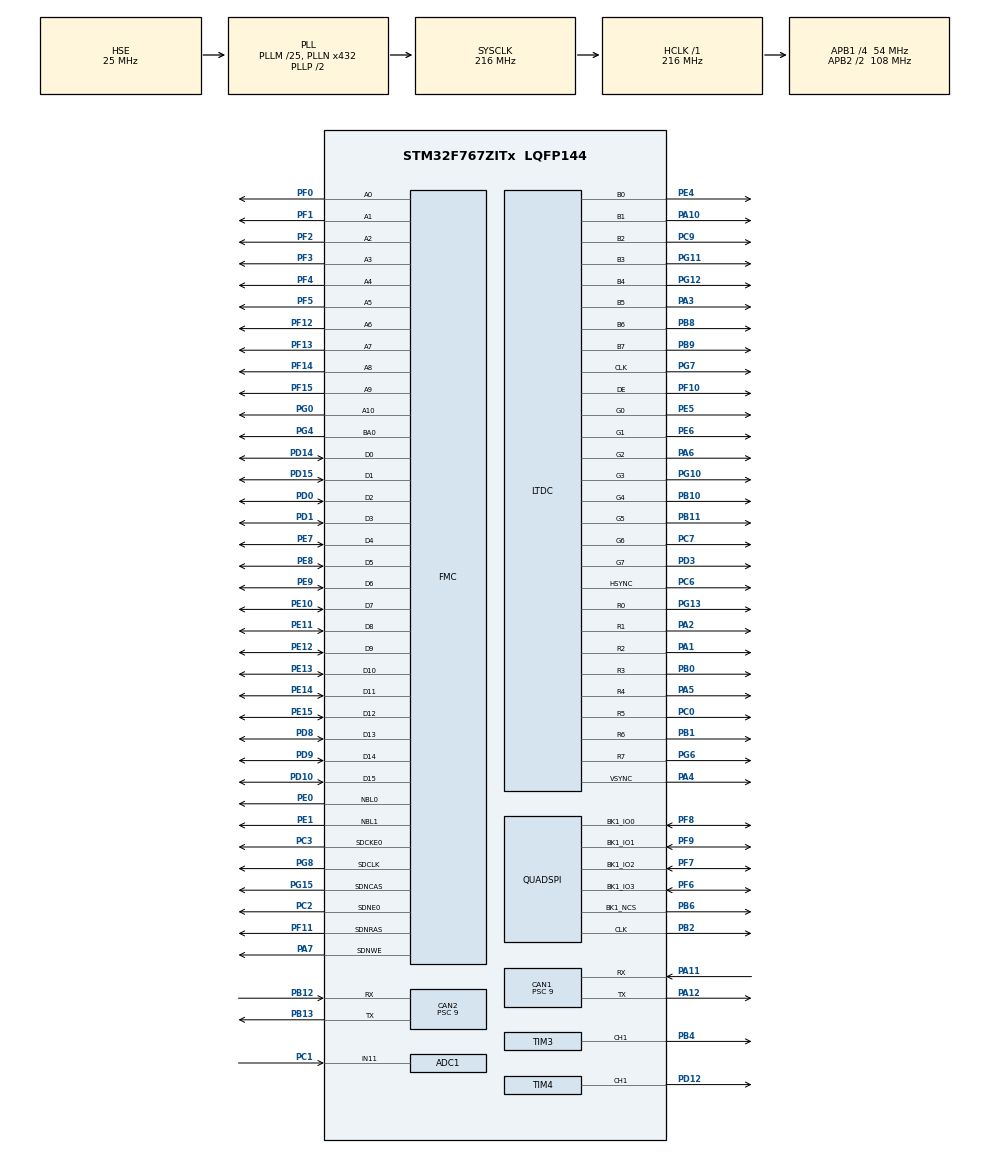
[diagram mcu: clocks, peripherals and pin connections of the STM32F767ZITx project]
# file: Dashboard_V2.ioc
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ADC1.Channel-0\#ChannelRegularConversion=ADC_CHANNEL_11
ADC1.Channel-1\#ChannelRegularConversion=ADC_CHANNEL_TEMPSENSOR
ADC1.ExternalTrigConv=ADC_EXTERNALTRIGCONV_T8_TRGO
ADC1.NbrOfConversion=2
ADC1.NbrOfConversionFlag=1
ADC1.Rank-0\#ChannelRegularConversion=1
ADC1.Rank-1\#ChannelRegularConversion=2
ADC1.SamplingTime-0\#ChannelRegularConversion=ADC_SAMPLETIME_480CYCLES
ADC1.SamplingTime-1\#ChannelRegularConversion=ADC_SAMPLETIME_480CYCLES
ADC1.ScanConvMode=ADC_SCAN_ENABLE
ADC1.master=1
CAN1.BS1=CAN_BS1_2TQ
CAN1.BS2=CAN_BS2_3TQ
CAN1.CalculateBaudRate=999999
CAN1.CalculateTimeBit=1000
CAN1.CalculateTimeQuantum=166.66666666666669
CAN1.NART=ENABLE
CAN1.Prescaler=9
CAN1.SJW=CAN_SJW_2TQ
CAN2.BS1=CAN_BS1_2TQ
CAN2.BS2=CAN_BS2_3TQ
CAN2.CalculateBaudRate=999999
CAN2.CalculateTimeBit=1000
CAN2.CalculateTimeQuantum=166.66666666666669
CAN2.NART=ENABLE
CAN2.Prescaler=9
CAN2.SJW=CAN_SJW_2TQ
DMA2D.ColorMode=DMA2D_OUTPUT_RGB888
Dma.Request0=TIM3_CH1/TRIG
Dma.Request1=TIM4_CH1
Dma.TIM3_CH1/TRIG.0.Direction=DMA_PERIPH_TO_MEMORY
Dma.TIM3_CH1/TRIG.0.FIFOMode=DMA_FIFOMODE_DISABLE
Dma.TIM3_CH1/TRIG.0.Instance=DMA1_Stream4
Dma.TIM3_CH1/TRIG.0.MemDataAlignment=DMA_MDATAALIGN_HALFWORD
Dma.TIM3_CH1/TRIG.0.MemInc=DMA_MINC_ENABLE
Dma.TIM3_CH1/TRIG.0.Mode=DMA_NORMAL
Dma.TIM3_CH1/TRIG.0.PeriphDataAlignment=DMA_PDATAALIGN_HALFWORD
Dma.TIM3_CH1/TRIG.0.PeriphInc=DMA_PINC_DISABLE
Dma.TIM3_CH1/TRIG.0.Priority=DMA_PRIORITY_LOW
Dma.TIM4_CH1.1.Direction=DMA_PERIPH_TO_MEMORY
Dma.TIM4_CH1.1.FIFOMode=DMA_FIFOMODE_DISABLE
Dma.TIM4_CH1.1.Instance=DMA1_Stream0
Dma.TIM4_CH1.1.MemDataAlignment=DMA_MDATAALIGN_HALFWORD
Dma.TIM4_CH1.1.MemInc=DMA_MINC_ENABLE
Dma.TIM4_CH1.1.Mode=DMA_NORMAL
Dma.TIM4_CH1.1.PeriphDataAlignment=DMA_PDATAALIGN_HALFWORD
Dma.TIM4_CH1.1.PeriphInc=DMA_PINC_DISABLE
Dma.TIM4_CH1.1.Priority=DMA_PRIORITY_LOW
FMC.CASLatency1=FMC_SDRAM_CAS_LATENCY_2
FMC.ExitSelfRefreshDelay1=7
FMC.LoadToActiveDelay1=2
FMC.RCDDelay1=2
FMC.RPDelay1=2
FMC.RPDelay2=2
FMC.ReadBurst1=FMC_SDRAM_RBURST_ENABLE
FMC.ReadBurst2=FMC_SDRAM_RBURST_ENABLE
FMC.RowCycleDelay1=6
FMC.RowCycleDelay2=6
FMC.SDClockPeriod1=FMC_SDRAM_CLOCK_PERIOD_2
FMC.SDClockPeriod2=FMC_SDRAM_CLOCK_PERIOD_2
FMC.SelfRefreshTime1=4
FMC.WriteRecoveryTime1=3
FREERTOS.Tasks01=hardwareTask,24,128,StartHardwareTask,Default,NULL,Dynamic,NULL,NULL;RPMLed,8,128,startRPMLed,Default,NULL,Dynamic,NULL,NULL;touchGFXTask,40,32768,startTouchGFXTask,Default,NULL,Dynamic,NULL,NULL;statusLedTask,8,128,startStatusLedTask,Default,NULL,Dynamic,NULL,NULL;DisplayDashboar,8,128,StartDisplayDashoard,Default,NULL,Dynamic,NULL,NULL
FREERTOS.configTOTAL_HEAP_SIZE=204800
JPEG.USE_JPEG_ENCODER=1
LTDC.ActiveW=800
LTDC.Alpha_L0=255
LTDC.FBStartAdress_L0=0xC0000000
LTDC.HBP=8
LTDC.HFP=8
LTDC.HSync=4
LTDC.ImageHeight_L0=480
LTDC.ImageWidth_L0=800
LTDC.Layers=0
LTDC.VBP=8
LTDC.VFP=8
LTDC.VSync=40
LTDC.WindowX1_L0=800
LTDC.WindowY1_L0=480
Mcu.Family=STM32F7
Mcu.Name=STM32F767ZITx
Mcu.Package=LQFP144
NVIC.ADC_IRQn=true\:5\:0\:false\:false\:true\:true\:true\:true\:true
NVIC.DMA1_Stream0_IRQn=true\:5\:0\:false\:false\:true\:true\:false\:true\:true
NVIC.DMA1_Stream4_IRQn=true\:5\:0\:false\:false\:true\:true\:false\:true\:true
NVIC.LTDC_IRQn=true\:5\:0\:false\:false\:true\:true\:true\:true\:true
NVIC.PriorityGroup=NVIC_PRIORITYGROUP_4
NVIC.TIM6_DAC_IRQn=true\:15\:0\:false\:false\:true\:false\:false\:true\:true
NVIC.TimeBase=TIM6_DAC_IRQn
NVIC.TimeBaseIP=TIM6
PA1.Mode=RGB888
PA1.Signal=LTDC_R2
PA10.Mode=RGB888
PA10.Signal=LTDC_B1
PA11.Mode=CAN_Activate
PA11.Signal=CAN1_RX
PA12.Mode=CAN_Activate
PA12.Signal=CAN1_TX
PA13.Mode=Trace_Asynchronous_SW
PA13.Signal=SYS_JTMS-SWDIO
PA14.Mode=Trace_Asynchronous_SW
PA14.Signal=SYS_JTCK-SWCLK
PA2.Mode=RGB888
PA2.Signal=LTDC_R1
PA3.Mode=RGB888
PA3.Signal=LTDC_B5
PA4.Mode=RGB888
PA4.Signal=LTDC_VSYNC
PA5.Mode=RGB888
PA5.Signal=LTDC_R4
PA6.Mode=RGB888
PA6.Signal=LTDC_G2
PA7.Signal=FMC_SDNWE
PB0.Mode=RGB888
PB0.Signal=LTDC_R3
PB1.Mode=RGB888
PB1.Signal=LTDC_R6
PB10.Mode=RGB888
PB10.Signal=LTDC_G4
PB11.Mode=RGB888
PB11.Signal=LTDC_G5
PB12.Mode=CAN_Activate
PB12.Signal=CAN2_RX
PB13.Mode=CAN_Activate
PB13.Signal=CAN2_TX
PB2.Mode=Single Bank 1
PB2.Signal=QUADSPI_CLK
PB3.Mode=Trace_Asynchronous_SW
PB3.Signal=SYS_JTDO-SWO
PB4.Signal=S_TIM3_CH1
PB6.Mode=Single Bank 1
PB6.Signal=QUADSPI_BK1_NCS
PB8.Mode=RGB888
PB8.Signal=LTDC_B6
PB9.Mode=RGB888
PB9.Signal=LTDC_B7
PC0.Mode=RGB888
PC0.Signal=LTDC_R5
PC1.Signal=ADCx_IN11
PC2.Mode=SdramChipSelect1_1
PC2.Signal=FMC_SDNE0
PC3.Mode=SdramChipSelect1_1
PC3.Signal=FMC_SDCKE0
PC6.Mode=RGB888
PC6.Signal=LTDC_HSYNC
PC7.Mode=RGB888
PC7.Signal=LTDC_G6
PC9.Mode=RGB888
PC9.Signal=LTDC_B2
PD0.Signal=FMC_D2_DA2
PD1.Signal=FMC_D3_DA3
PD10.Signal=FMC_D15_DA15
PD12.Signal=S_TIM4_CH1
PD14.Signal=FMC_D0_DA0
PD15.Signal=FMC_D1_DA1
PD3.Mode=RGB888
PD3.Signal=LTDC_G7
PD8.Signal=FMC_D13_DA13
PD9.Signal=FMC_D14_DA14
PE0.Signal=FMC_NBL0
PE1.Signal=FMC_NBL1
PE10.Signal=FMC_D7_DA7
PE11.Signal=FMC_D8_DA8
PE12.Signal=FMC_D9_DA9
PE13.Signal=FMC_D10_DA10
PE14.Signal=FMC_D11_DA11
PE15.Signal=FMC_D12_DA12
PE4.Mode=RGB888
PE4.Signal=LTDC_B0
PE5.Mode=RGB888
PE5.Signal=LTDC_G0
PE6.Mode=RGB888
PE6.Signal=LTDC_G1
PE7.Signal=FMC_D4_DA4
PE8.Signal=FMC_D5_DA5
PE9.Signal=FMC_D6_DA6
PF0.Signal=FMC_A0
PF1.Signal=FMC_A1
PF10.Mode=RGB888
PF10.Signal=LTDC_DE
PF11.Signal=FMC_SDNRAS
PF12.Signal=FMC_A6
PF13.Signal=FMC_A7
PF14.Signal=FMC_A8
PF15.Signal=FMC_A9
PF2.Signal=FMC_A2
PF3.Signal=FMC_A3
PF4.Signal=FMC_A4
PF5.Signal=FMC_A5
PF6.Mode=Single Bank 1
PF6.Signal=QUADSPI_BK1_IO3
PF7.Mode=Single Bank 1
PF7.Signal=QUADSPI_BK1_IO2
PF8.Mode=Single Bank 1
PF8.Signal=QUADSPI_BK1_IO0
PF9.Mode=Single Bank 1
PF9.Signal=QUADSPI_BK1_IO1
PG0.Signal=FMC_A10
PG10.Mode=RGB888
PG10.Signal=LTDC_G3
PG11.Mode=RGB888
PG11.Signal=LTDC_B3
PG12.Mode=RGB888
PG12.Signal=LTDC_B4
PG13.Mode=RGB888
PG13.Signal=LTDC_R0
PG15.Signal=FMC_SDNCAS
PG4.Signal=FMC_A14_BA0
PG6.Mode=RGB888
PG6.Signal=LTDC_R7
PG7.Mode=RGB888
PG7.Signal=LTDC_CLK
PG8.Signal=FMC_SDCLK
PH0/OSC_IN.Mode=HSE-External-Oscillator
PH0/OSC_IN.Signal=RCC_OSC_IN
PH1/OSC_OUT.Mode=HSE-External-Oscillator
PH1/OSC_OUT.Signal=RCC_OSC_OUT
ProjectManager.HeapSize=0x200
ProjectManager.StackSize=0x400
ProjectManager.TargetToolchain=STM32CubeIDE
QUADSPI.ChipSelectHighTime=QSPI_CS_HIGH_TIME_6_CYCLE
QUADSPI.ClockPrescaler=3
QUADSPI.FlashSize=23
QUADSPI.SampleShifting=QSPI_SAMPLE_SHIFTING_HALFCYCLE
RCC.AHBFreq_Value=216000000
RCC.APB1CLKDivider=RCC_HCLK_DIV4
RCC.APB1Freq_Value=54000000
RCC.APB1TimFreq_Value=108000000
RCC.APB2CLKDivider=RCC_HCLK_DIV2
RCC.APB2Freq_Value=108000000
RCC.APB2TimFreq_Value=216000000
RCC.CortexFreq_Value=216000000
RCC.HCLKFreq_Value=216000000
RCC.HSE_VALUE=25000000
RCC.HSI_VALUE=16000000
RCC.LSE_VALUE=32768
RCC.PLLM=25
RCC.PLLN=432
RCC.PLLSAIN=279
RCC.PLLSAIR=3
RCC.PLLSAIRDiv=RCC_PLLSAIDIVR_4
RCC.PLLSourceVirtual=RCC_PLLSOURCE_HSE
RCC.SYSCLKFreq_VALUE=216000000
RCC.SYSCLKSource=RCC_SYSCLKSOURCE_PLLCLK
RCC.USBFreq_Value=216000000
RCC.VCOOutputFreq_Value=432000000
SH.ADCx_IN11.0=ADC1_IN11,IN11
SH.FMC_A0.0=FMC_A0,11b-sda1
SH.FMC_A1.0=FMC_A1,11b-sda1
SH.FMC_A10.0=FMC_A10,11b-sda1
SH.FMC_A14_BA0.0=FMC_BA0,TwoSdramBanks1
SH.FMC_A2.0=FMC_A2,11b-sda1
SH.FMC_A3.0=FMC_A3,11b-sda1
SH.FMC_A4.0=FMC_A4,11b-sda1
SH.FMC_A5.0=FMC_A5,11b-sda1
SH.FMC_A6.0=FMC_A6,11b-sda1
SH.FMC_A7.0=FMC_A7,11b-sda1
SH.FMC_A8.0=FMC_A8,11b-sda1
SH.FMC_A9.0=FMC_A9,11b-sda1
SH.FMC_D0_DA0.0=FMC_D0,sd-16b-d1
SH.FMC_D10_DA10.0=FMC_D10,sd-16b-d1
SH.FMC_D11_DA11.0=FMC_D11,sd-16b-d1
SH.FMC_D12_DA12.0=FMC_D12,sd-16b-d1
SH.FMC_D13_DA13.0=FMC_D13,sd-16b-d1
SH.FMC_D14_DA14.0=FMC_D14,sd-16b-d1
SH.FMC_D15_DA15.0=FMC_D15,sd-16b-d1
SH.FMC_D1_DA1.0=FMC_D1,sd-16b-d1
SH.FMC_D2_DA2.0=FMC_D2,sd-16b-d1
SH.FMC_D3_DA3.0=FMC_D3,sd-16b-d1
SH.FMC_D4_DA4.0=FMC_D4,sd-16b-d1
SH.FMC_D5_DA5.0=FMC_D5,sd-16b-d1
SH.FMC_D6_DA6.0=FMC_D6,sd-16b-d1
SH.FMC_D7_DA7.0=FMC_D7,sd-16b-d1
SH.FMC_D8_DA8.0=FMC_D8,sd-16b-d1
SH.FMC_D9_DA9.0=FMC_D9,sd-16b-d1
SH.FMC_NBL0.0=FMC_NBL0,Sd2ByteEnable1
SH.FMC_NBL1.0=FMC_NBL1,Sd2ByteEnable1
SH.FMC_SDCLK.0=FMC_SDCLK,11b-sda1
SH.FMC_SDNCAS.0=FMC_SDNCAS,11b-sda1
SH.FMC_SDNRAS.0=FMC_SDNRAS,11b-sda1
SH.FMC_SDNWE.0=FMC_SDNWE,11b-sda1
SH.S_TIM3_CH1.0=TIM3_CH1,PWM Generation1 CH1
SH.S_TIM4_CH1.0=TIM4_CH1,PWM Generation1 CH1
STMicroelectronics.X-CUBE-TOUCHGFX.4.20.0.ApplicationCcGraphicsJjApplication=TouchGFXOoGenerator
STMicroelectronics.X-CUBE-TOUCHGFX.4.20.0.tgfx_address1=0xC0000000
STMicroelectronics.X-CUBE-TOUCHGFX.4.20.0.tgfx_display_interface=disp_ltdc
STMicroelectronics.X-CUBE-TOUCHGFX.4.20.0.tgfx_hardware_accelerator=dma_2d
STMicroelectronics.X-CUBE-TOUCHGFX.4.20.0.tgfx_location=By Address
STMicroelectronics.X-CUBE-TOUCHGFX.4.20.0.tgfx_video=Hardware
STMicroelectronics.X-CUBE-TOUCHGFX.4.20.0.tgfx_vsync=vsync_ltdc
STMicroelectronics.X-CUBE-TOUCHGFX.4.20.0_IsPackSelfContextualization=true
TIM3.Channel-PWM\ Generation1\ CH1=TIM_CHANNEL_1
TIM3.Period=134
TIM4.Channel-PWM\ Generation1\ CH1=TIM_CHANNEL_1
TIM4.Period=215
TIM8.Channel-PWM\ Generation1\ No\ Output=TIM_CHANNEL_1
TIM8.Period=5000-1
TIM8.Prescaler=216-1
VP_ADC1_TempSens_Input.Mode=IN-TempSens
VP_CRC_VS_CRC.Mode=CRC_Activate
VP_DMA2D_VS_DMA2D.Mode=DMA2D_Activate
VP_FREERTOS_VS_CMSIS_V2.Mode=CMSIS_V2
VP_JPEG_VS_JPEG.Mode=JPEG_Activate
VP_STMicroelectronics.X-CUBE-TOUCHGFX_VS_GraphicsJjApplication_4.20.0.Mode=GraphicsJjApplication
VP_SYS_VS_tim6.Mode=TIM6
VP_TIM3_VS_ClockSourceINT.Mode=Internal
VP_TIM4_VS_ClockSourceINT.Mode=Internal
VP_TIM8_VS_ClockSourceINT.Mode=Internal
VP_TIM8_VS_no_output1.Mode=PWM Generation1 No Output
board=custom

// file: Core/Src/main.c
/* USER CODE BEGIN Header */
/**
  ******************************************************************************
  * @file           : main.c
  * @brief          : Main program body
  ******************************************************************************
  * @attention
  *
  * <h2><center>&copy; Copyright (c) 2021 STMicroelectronics.
  * All rights reserved.</center></h2>
  *
  * This software component is licensed by ST under Ultimate Liberty license
  * SLA0044, the "License"; You may not use this file except in compliance with
  * the License. You may obtain a copy of the License at:
  *                             www.st.com/SLA0044
  *
  ******************************************************************************
  */
/* USER CODE END Header */
#include "main.h"
#include "cmsis_os.h"
#include "adc.h"
#include "can.h"
#include "crc.h"
#include "dma.h"
#include "dma2d.h"
#include "jpeg.h"
#include "ltdc.h"
#include "quadspi.h"
#include "tim.h"
#include "gpio.h"
#include "fmc.h"
#include "app_touchgfx.h"

/* USER CODE BEGIN Includes */
#include "at25sf128a.h"
#include "structs/ecumaster.h"

/* USER CODE END Includes */

void SystemClock_Config(void);
void MX_FREERTOS_Init(void);

int main(void)
{

  /* MCU Configuration--------------------------------------------------------*/

  /* Reset of all peripherals, Initializes the Flash interface and the Systick. */
  HAL_Init();

  /* Configure the system clock */
  SystemClock_Config();

  /* Initialize all configured peripherals */
  MX_GPIO_Init();
  MX_CRC_Init();
  MX_DMA2D_Init();
  MX_LTDC_Init();
  MX_ADC1_Init();
  MX_CAN1_Init();
  MX_CAN2_Init();
  MX_FMC_Init();
  MX_JPEG_Init();
  MX_QUADSPI_Init();
  MX_TIM3_Init();
  MX_TIM4_Init();
  MX_DMA_Init();
  MX_TIM8_Init();
  MX_TouchGFX_Init();
  /* Call PreOsInit function */
  MX_TouchGFX_PreOSInit();
  /* USER CODE BEGIN 2 */
  FLASH_QSPI_Init();
  /* USER CODE END 2 */

  /* Init scheduler */
  osKernelInitialize();  /* Call init function for freertos objects (in freertos.c) */
  MX_FREERTOS_Init();

  /* Start scheduler */
  osKernelStart();

  /* We should never get here as control is now taken by the scheduler */
  /* Infinite loop */
  while (1)
  {

  }
}

void SystemClock_Config(void)
{
  RCC_OscInitTypeDef RCC_OscInitStruct = {0};
  RCC_ClkInitTypeDef RCC_ClkInitStruct = {0};

  /** Configure the main internal regulator output voltage
  */
  __HAL_RCC_PWR_CLK_ENABLE();
  __HAL_PWR_VOLTAGESCALING_CONFIG(PWR_REGULATOR_VOLTAGE_SCALE1);

  /** Initializes the RCC Oscillators according to the specified parameters
  * in the RCC_OscInitTypeDef structure.
  */
  RCC_OscInitStruct.OscillatorType = RCC_OSCILLATORTYPE_HSE;
  RCC_OscInitStruct.HSEState = RCC_HSE_ON;
  RCC_OscInitStruct.PLL.PLLState = RCC_PLL_ON;
  RCC_OscInitStruct.PLL.PLLSource = RCC_PLLSOURCE_HSE;
  RCC_OscInitStruct.PLL.PLLM = 25;
  RCC_OscInitStruct.PLL.PLLN = 432;
  RCC_OscInitStruct.PLL.PLLP = RCC_PLLP_DIV2;
  RCC_OscInitStruct.PLL.PLLQ = 2;
  RCC_OscInitStruct.PLL.PLLR = 2;
  if (HAL_RCC_OscConfig(&RCC_OscInitStruct) != HAL_OK)
  {
    Error_Handler();
  }

  /** Activate the Over-Drive mode
  */
  if (HAL_PWREx_EnableOverDrive() != HAL_OK)
  {
    Error_Handler();
  }

  /** Initializes the CPU, AHB and APB buses clocks
  */
  RCC_ClkInitStruct.ClockType = RCC_CLOCKTYPE_HCLK|RCC_CLOCKTYPE_SYSCLK
                              |RCC_CLOCKTYPE_PCLK1|RCC_CLOCKTYPE_PCLK2;
  RCC_ClkInitStruct.SYSCLKSource = RCC_SYSCLKSOURCE_PLLCLK;
  RCC_ClkInitStruct.AHBCLKDivider = RCC_SYSCLK_DIV1;
  RCC_ClkInitStruct.APB1CLKDivider = RCC_HCLK_DIV4;
  RCC_ClkInitStruct.APB2CLKDivider = RCC_HCLK_DIV2;

  if (HAL_RCC_ClockConfig(&RCC_ClkInitStruct, FLASH_LATENCY_7) != HAL_OK)
  {
    Error_Handler();
  }
}

void HAL_TIM_PeriodElapsedCallback(TIM_HandleTypeDef *htim)
{
  if (htim->Instance == TIM6) {
    HAL_IncTick();
  }
}

void Error_Handler(void)
{
  __disable_irq();
  while (1)
  {
  }
}

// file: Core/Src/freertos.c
/* USER CODE BEGIN Header */
/**
 ******************************************************************************
 * File Name          : freertos.c
 * Description        : Code for freertos applications
 ******************************************************************************
 * @attention
 *
 * Copyright (c) 2022 STMicroelectronics.
 * All rights reserved.
 *
 * This software is licensed under terms that can be found in the LICENSE file
 * in the root directory of this software component.
 * If no LICENSE file comes with this software, it is provided AS-IS.
 *
 ******************************************************************************
 */
/* USER CODE END Header */

#include "FreeRTOS.h"
#include "task.h"
#include "main.h"
#include "cmsis_os.h"

/* USER CODE BEGIN Includes */
#include "adc.h"
#include "app_touchgfx.h"
#include "can.h"
#include "gpio.h"
#include "structs/ecumaster.h"
#include "structs/display_data.h"
#include "structs/telemetry_data.h"
#include "tim.h"
#include "WS2812_driver.h"
#include <math.h>

/* USER CODE END Includes */

/* USER CODE BEGIN PD */
#define PWM_CHANGE 5
/* USER CODE END PD */

/* USER CODE BEGIN Variables */
DisplaySetup_t displaySetup =
{ 70, 2, 110, 110, 110 };
EcumasterData_t ecumasterData;
TelemetryData_t telemetryData;

/* USER CODE END Variables */
/* Definitions for hardwareTask */
osThreadId_t hardwareTaskHandle;
const osThreadAttr_t hardwareTask_attributes = {
  .name = "hardwareTask",
  .stack_size = 128 * 4,
  .priority = (osPriority_t) osPriorityNormal,
};
/* Definitions for RPMLed */
osThreadId_t RPMLedHandle;
const osThreadAttr_t RPMLed_attributes = {
  .name = "RPMLed",
  .stack_size = 128 * 4,
  .priority = (osPriority_t) osPriorityLow,
};
/* Definitions for touchGFXTask */
osThreadId_t touchGFXTaskHandle;
const osThreadAttr_t touchGFXTask_attributes = {
  .name = "touchGFXTask",
  .stack_size = 32768 * 4,
  .priority = (osPriority_t) osPriorityHigh,
};
/* Definitions for statusLedTask */
osThreadId_t statusLedTaskHandle;
const osThreadAttr_t statusLedTask_attributes = {
  .name = "statusLedTask",
  .stack_size = 128 * 4,
  .priority = (osPriority_t) osPriorityLow,
};
/* Definitions for DisplayDashboar */
osThreadId_t DisplayDashboarHandle;
const osThreadAttr_t DisplayDashboar_attributes = {
  .name = "DisplayDashboar",
  .stack_size = 128 * 4,
  .priority = (osPriority_t) osPriorityLow,
};

void StartHardwareTask(void *argument);
void startRPMLed(void *argument);
void startTouchGFXTask(void *argument);
void startStatusLedTask(void *argument);
void StartDisplayDashoard(void *argument);

void MX_FREERTOS_Init(void); /* (MISRA C 2004 rule 8.1) */

void MX_FREERTOS_Init(void) {

  /* Create the thread(s) */
  /* creation of hardwareTask */
  hardwareTaskHandle = osThreadNew(StartHardwareTask, NULL, &hardwareTask_attributes);

  /* creation of RPMLed */
  RPMLedHandle = osThreadNew(startRPMLed, NULL, &RPMLed_attributes);

  /* creation of touchGFXTask */
  touchGFXTaskHandle = osThreadNew(startTouchGFXTask, NULL, &touchGFXTask_attributes);

  /* creation of statusLedTask */
  statusLedTaskHandle = osThreadNew(startStatusLedTask, NULL, &statusLedTask_attributes);

  /* creation of DisplayDashboar */
  DisplayDashboarHandle = osThreadNew(StartDisplayDashoard, NULL, &DisplayDashboar_attributes);

}

void StartHardwareTask(void *argument)
{
  /* USER CODE BEGIN StartHardwareTask */
	CanCommunicationInit();
	/* Infinite loop */
	for (;;)
	{
		osDelay(1);
	}
  /* USER CODE END StartHardwareTask */
}

void startRPMLed(void *argument)
{
  /* USER CODE BEGIN startRPMLed */
	WS2812_Init();
	/* Infinite loop */
	for (;;)
	{
		uint8_t displayMode = telemetryData.gear == 0 ? 0 : displaySetup.ledBarMode;
		updateLeds(ecumasterData.rpm, displayMode);
		osDelay(50);
	}
  /* USER CODE END startRPMLed */
}

void startTouchGFXTask(void *argument)
{
	for (;;)
	{
		osDelay(1);
	}
}

void startStatusLedTask(void *argument)
{
	for (;;)
	{
		osDelay(1);
	}
}

void StartDisplayDashoard(void *argument)
{
  for(;;)
  {
    osDelay(1);
  }
}
